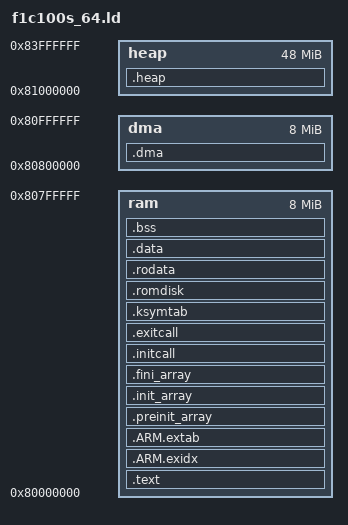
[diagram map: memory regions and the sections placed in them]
OUTPUT_FORMAT("elf32-littlearm", "elf32-bigarm", "elf32-littlearm")
OUTPUT_ARCH(arm)
ENTRY(__vector)

MEMORY
{
	ram  : org = 0x80000000, len = 8M
	dma  : org = 0x80800000, len = 8M
	heap : org = 0x81000000, len = 48M
}

SECTIONS
{
  .text :
  {
    PROVIDE(__image_start = .);
	  PROVIDE(__text_start = .);
    PROVIDE(__vectors_start = .);
    *(.vectors);
    . = ALIGN(4);
    PROVIDE(__vectors_end = .);
		*(.text*)
    . = ALIGN(4);
		*(.init.text)
    . = ALIGN(4);
		*(.exit.text)
    . = ALIGN(4);
		*(.glue*)
    . = ALIGN(4);
		*(.note.gnu.build-id)
    . = ALIGN(4);
    etext = .;
    PROVIDE(__text_end = .);
  } > ram

	.ARM.exidx ALIGN(8) :
	{
		PROVIDE (__exidx_start = .);
		*(.ARM.exidx*)
		PROVIDE (__exidx_end = .);
	} > ram

	.ARM.extab ALIGN(8) :
	{
		PROVIDE (__extab_start = .);
		*(.ARM.extab*)
		PROVIDE (__extab_end = .);
	} > ram

  .preinit_array     :
	{
		PROVIDE_HIDDEN (__preinit_array_start = .);
		KEEP (*(.preinit_array*))
		PROVIDE_HIDDEN (__preinit_array_end = .);
	} > ram

	.init_array :
	{
		PROVIDE_HIDDEN (__init_array_start = .);
		KEEP (*(SORT(.init_array.*)))
		KEEP (*(.init_array*))
		PROVIDE_HIDDEN (__init_array_end = .);
	} > ram

	.fini_array :
	{
		PROVIDE_HIDDEN (__fini_array_start = .);
		KEEP (*(SORT(.fini_array.*)))
		KEEP (*(.fini_array*))
		PROVIDE_HIDDEN (__fini_array_end = .);
	} > ram

	.initcall ALIGN(8) :
	{
		PROVIDE(__initcall_start = .);
		KEEP(*(.initcall_0.text))
		KEEP(*(.initcall_1.text))
		KEEP(*(.initcall_2.text))
		KEEP(*(.initcall_3.text))
		KEEP(*(.initcall_4.text))
		KEEP(*(.initcall_5.text))
		KEEP(*(.initcall_6.text))
		KEEP(*(.initcall_7.text))
		KEEP(*(.initcall_8.text))
		KEEP(*(.initcall_9.text))
		PROVIDE(__initcall_end = .);
	} > ram

	.exitcall ALIGN(8) :
	{
		PROVIDE(__exitcall_start = .);
		KEEP(*(.exitcall_9.text))
		KEEP(*(.exitcall_8.text))
		KEEP(*(.exitcall_7.text))
		KEEP(*(.exitcall_6.text))
		KEEP(*(.exitcall_5.text))
		KEEP(*(.exitcall_4.text))
		KEEP(*(.exitcall_3.text))
		KEEP(*(.exitcall_2.text))
		KEEP(*(.exitcall_1.text))
		KEEP(*(.exitcall_0.text))
		PROVIDE(__exitcall_end = .);
	} > ram

	.ksymtab ALIGN(16) :
	{
		PROVIDE(__ksymtab_start = .);
		KEEP(*(.ksymtab.text))
		PROVIDE(__ksymtab_end = .);
	} > ram

	.romdisk ALIGN(8) :
	{
		PROVIDE(__romdisk_start = .);
		KEEP(*(.romdisk))
		PROVIDE(__romdisk_end = .);
	} > ram

	.rodata ALIGN(8) :
	{
		PROVIDE(__rodata_start = .);
		*(SORT_BY_ALIGNMENT(SORT_BY_NAME(.rodata*)))
		PROVIDE(__rodata_end = .);
	} > ram

	.data ALIGN(8) :
	{
		PROVIDE(__data_start = .);	
		*(.data*)
		. = ALIGN(8);
  		PROVIDE(__data_end = .);
		PROVIDE(__image_end = .);
	} > ram

	.bss ALIGN(8) (NOLOAD) :
	{
		PROVIDE(__bss_start = .);
		*(.bss*)
		*(.sbss*)
		*(COMMON)
		. = ALIGN(8);
		PROVIDE(__bss_end = .);
	} > ram

	.dma ALIGN(8) (NOLOAD) :
	{
		PROVIDE(__dma_start = ORIGIN(dma));
		PROVIDE(__dma_end = ORIGIN(dma) + LENGTH(dma));
	} > dma

	.heap ALIGN(8) (NOLOAD) :
	{
		PROVIDE(__heap_start = ORIGIN(heap));
		PROVIDE(__heap_end = ORIGIN(heap) + LENGTH(heap));
	} > heap
}

